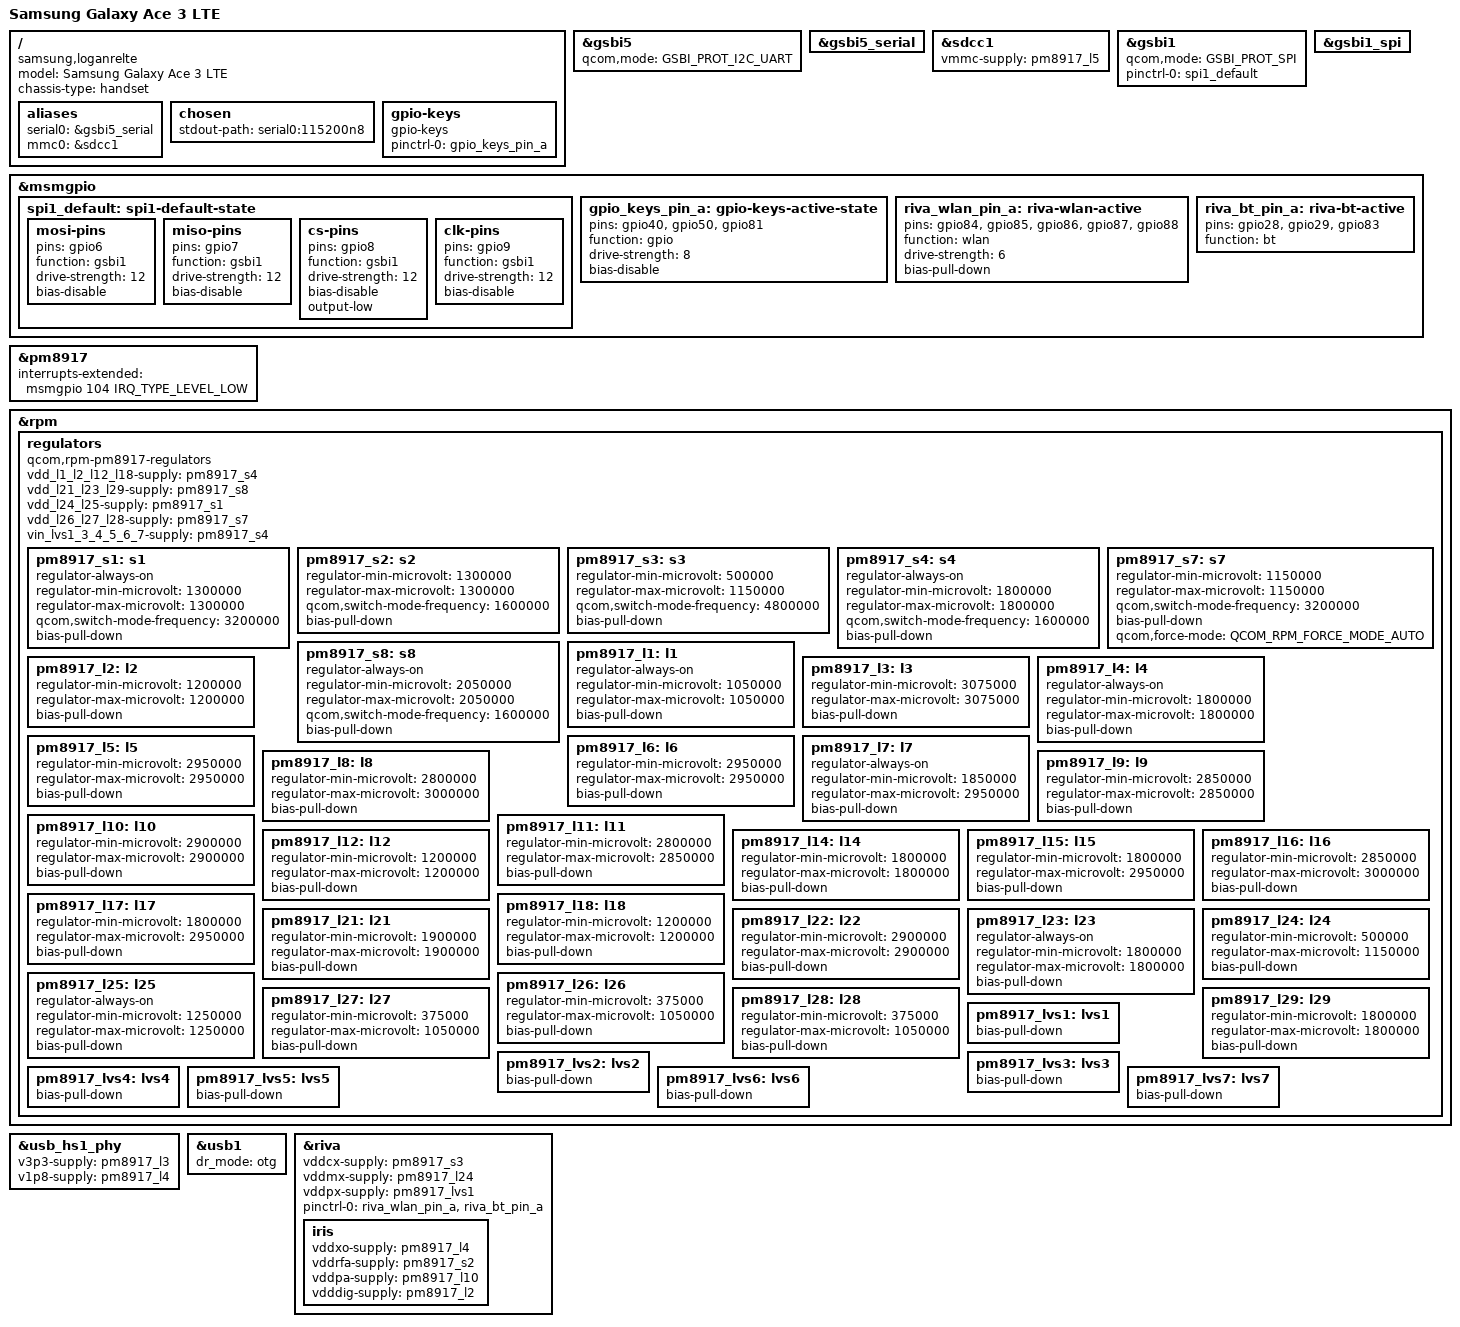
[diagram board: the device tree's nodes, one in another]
// SPDX-License-Identifier: GPL-2.0
// Heavily based on qcom-msm8960-samsung-expressatt.dts

/*
 * TODO:
 * - Enable the uSD card slot
 * - Enable the touchscreen
 * - Enable the screen
 */
#include <dt-bindings/input/input.h>
#include <dt-bindings/reset/qcom,gcc-msm8960.h>

#include "qcom-msm8930-pm8917.dtsi"
#include <dt-bindings/gpio/gpio.h>
#include <dt-bindings/pinctrl/qcom,pmic-gpio.h>
#include <dt-bindings/input/gpio-keys.h>

/ {
	model = "Samsung Galaxy Ace 3 LTE";
	compatible = "samsung,loganrelte", "qcom,msm8930";
	chassis-type = "handset";

	aliases {
		serial0 = &gsbi5_serial;
		mmc0 = &sdcc1; /* SDCC1 eMMC slot */
	};

	chosen {
		stdout-path = "serial0:115200n8";
	};

	gpio-keys {
		compatible = "gpio-keys";
		pinctrl-names = "default";
		pinctrl-0 = <&gpio_keys_pin_a>;
	};
};

&gsbi5 {
	qcom,mode = <GSBI_PROT_I2C_UART>;
	status = "okay";
};

&gsbi5_serial {
	status = "okay";
};

&sdcc1 {
	vmmc-supply = <&pm8917_l5>;
	status = "okay";
};

&gsbi1 {
	qcom,mode = <GSBI_PROT_SPI>;
	pinctrl-0 = <&spi1_default>;
	pinctrl-names = "default";
	status = "okay";
};

&gsbi1_spi {
	status = "okay";
};

&msmgpio {
	spi1_default: spi1-default-state {
		mosi-pins {
			pins = "gpio6";
			function = "gsbi1";
			drive-strength = <12>;
			bias-disable;
		};

		miso-pins {
			pins = "gpio7";
			function = "gsbi1";
			drive-strength = <12>;
			bias-disable;
		};

		cs-pins {
			pins = "gpio8";
			function = "gsbi1";
			drive-strength = <12>;
			bias-disable;
			output-low;
		};

		clk-pins {
			pins = "gpio9";
			function = "gsbi1";
			drive-strength = <12>;
			bias-disable;
		};
	};

	gpio_keys_pin_a: gpio-keys-active-state {
		pins = "gpio40", "gpio50", "gpio81";
		function = "gpio";
		drive-strength = <8>;
		bias-disable;
	};

	riva_wlan_pin_a: riva-wlan-active {
		pins = "gpio84", "gpio85", "gpio86", "gpio87", "gpio88";
		function = "wlan";

		drive-strength = <6>;
		bias-pull-down;
	};

	riva_bt_pin_a: riva-bt-active {
		pins = "gpio28", "gpio29", "gpio83"; // 1 extra ?
		function = "bt";
	};
};

&pm8917 {
	interrupts-extended = <&msmgpio 104 IRQ_TYPE_LEVEL_LOW>;
};

&rpm {
	regulators {
		compatible = "qcom,rpm-pm8917-regulators";
		vdd_l1_l2_l12_l18-supply = <&pm8917_s4>;
		vdd_l21_l23_l29-supply = <&pm8917_s8>;
		vdd_l24_l25-supply = <&pm8917_s1>;
		vdd_l26_l27_l28-supply = <&pm8917_s7>;
		vin_lvs1_3_4_5_6_7-supply = <&pm8917_s4>;

		/* Buck SMPS */
		pm8917_s1: s1 {
			regulator-always-on;
			regulator-min-microvolt = <1300000>;
			regulator-max-microvolt = <1300000>;
			qcom,switch-mode-frequency = <3200000>;
			bias-pull-down;
		};

		pm8917_s2: s2 {
			regulator-min-microvolt = <1300000>;
			regulator-max-microvolt = <1300000>;
			qcom,switch-mode-frequency = <1600000>;
			bias-pull-down;
		};

		pm8917_s3: s3 {
			regulator-min-microvolt = <500000>;
			regulator-max-microvolt = <1150000>;
			qcom,switch-mode-frequency = <4800000>;
			bias-pull-down;
		};

		pm8917_s4: s4 {
			regulator-always-on;
			regulator-min-microvolt = <1800000>;
			regulator-max-microvolt = <1800000>;
			qcom,switch-mode-frequency = <1600000>;
			bias-pull-down;
		};

		pm8917_s7: s7 {
			regulator-min-microvolt = <1150000>;
			regulator-max-microvolt = <1150000>;
			qcom,switch-mode-frequency = <3200000>;
			bias-pull-down;
			qcom,force-mode = <QCOM_RPM_FORCE_MODE_AUTO>;
		};

		pm8917_s8: s8 {
			regulator-always-on;
			regulator-min-microvolt = <2050000>;
			regulator-max-microvolt = <2050000>;
			qcom,switch-mode-frequency = <1600000>;
			bias-pull-down;
		};

		/* PMOS LDO */
		pm8917_l1: l1 {
			regulator-always-on;
			regulator-min-microvolt = <1050000>;
			regulator-max-microvolt = <1050000>;
			bias-pull-down;
		};

		pm8917_l2: l2 {
			regulator-min-microvolt = <1200000>;
			regulator-max-microvolt = <1200000>;
			bias-pull-down;
		};

		pm8917_l3: l3 {
			regulator-min-microvolt = <3075000>;
			regulator-max-microvolt = <3075000>;
			bias-pull-down;
		};

		pm8917_l4: l4 {
			regulator-always-on;
			regulator-min-microvolt = <1800000>;
			regulator-max-microvolt = <1800000>;
			bias-pull-down;
		};

		pm8917_l5: l5 {
			regulator-min-microvolt = <2950000>;
			regulator-max-microvolt = <2950000>;
			bias-pull-down;
		};

		pm8917_l6: l6 {
			regulator-min-microvolt = <2950000>;
			regulator-max-microvolt = <2950000>;
			bias-pull-down;
		};

		pm8917_l7: l7 {
			regulator-always-on;
			regulator-min-microvolt = <1850000>;
			regulator-max-microvolt = <2950000>;
			bias-pull-down;
		};

		pm8917_l8: l8 {
			regulator-min-microvolt = <2800000>;
			regulator-max-microvolt = <3000000>;
			bias-pull-down;
		};

		pm8917_l9: l9 {
			regulator-min-microvolt = <2850000>;
			regulator-max-microvolt = <2850000>;
			bias-pull-down;
		};

		pm8917_l10: l10 {
			regulator-min-microvolt = <2900000>;
			regulator-max-microvolt = <2900000>;
			bias-pull-down;
		};

		pm8917_l11: l11 {
			regulator-min-microvolt = <2800000>;
			regulator-max-microvolt = <2850000>;
			bias-pull-down;
		};

		pm8917_l12: l12 {
			regulator-min-microvolt = <1200000>;
			regulator-max-microvolt = <1200000>;
			bias-pull-down;
		};

		pm8917_l14: l14 {
			regulator-min-microvolt = <1800000>;
			regulator-max-microvolt = <1800000>;
			bias-pull-down;
		};

		pm8917_l15: l15 {
			regulator-min-microvolt = <1800000>;
			regulator-max-microvolt = <2950000>;
			bias-pull-down;
		};

		pm8917_l16: l16 {
			regulator-min-microvolt = <2850000>;
			regulator-max-microvolt = <3000000>;
			bias-pull-down;
		};

		pm8917_l17: l17 {
			regulator-min-microvolt = <1800000>;
			regulator-max-microvolt = <2950000>;
			bias-pull-down;
		};

		pm8917_l18: l18 {
			regulator-min-microvolt = <1200000>;
			regulator-max-microvolt = <1200000>;
			bias-pull-down;
		};

		pm8917_l21: l21 {
			regulator-min-microvolt = <1900000>;
			regulator-max-microvolt = <1900000>;
			bias-pull-down;
		};

		pm8917_l22: l22 {
			regulator-min-microvolt = <2900000>;
			regulator-max-microvolt = <2900000>;
			bias-pull-down;
		};

		pm8917_l23: l23 {
			regulator-always-on;
			regulator-min-microvolt = <1800000>;
			regulator-max-microvolt = <1800000>;
			bias-pull-down;
		};

		pm8917_l24: l24 {
			regulator-min-microvolt = <500000>;
			regulator-max-microvolt = <1150000>;
			bias-pull-down;
		};

		pm8917_l25: l25 {
			regulator-always-on;
			regulator-min-microvolt = <1250000>;
			regulator-max-microvolt = <1250000>;
			bias-pull-down;
		};

		pm8917_l26: l26 {
			regulator-min-microvolt = <375000>;
			regulator-max-microvolt = <1050000>;
			bias-pull-down;
		};

		pm8917_l27: l27 {
			regulator-min-microvolt = <375000>;
			regulator-max-microvolt = <1050000>;
			bias-pull-down;
		};

		pm8917_l28: l28 {
			regulator-min-microvolt = <375000>;
			regulator-max-microvolt = <1050000>;
			bias-pull-down;
		};

		pm8917_l29: l29 {
			regulator-min-microvolt = <1800000>;
			regulator-max-microvolt = <1800000>;
			bias-pull-down;
		};

		// TODO: l30 - l36

		/* Low Voltage Switch */
		pm8917_lvs1: lvs1 {
			bias-pull-down;
		};

		pm8917_lvs2: lvs2 {
			bias-pull-down;
		};

		pm8917_lvs3: lvs3 {
			bias-pull-down;
		};

		pm8917_lvs4: lvs4 {
			bias-pull-down;
		};

		pm8917_lvs5: lvs5 {
			bias-pull-down;
		};

		pm8917_lvs6: lvs6 {
			bias-pull-down;
		};

		pm8917_lvs7: lvs7 {
			bias-pull-down;
		};

		// TODO: boost and usb
	};
};

&usb_hs1_phy {
	v3p3-supply = <&pm8917_l3>;
	v1p8-supply = <&pm8917_l4>;
};

&usb1 {
	dr_mode = "otg";
	status = "okay";
};

&riva {
	vddcx-supply = <&pm8917_s3>;
	vddmx-supply = <&pm8917_l24>;
	vddpx-supply = <&pm8917_lvs1>;

	pinctrl-0 = <&riva_wlan_pin_a>, <&riva_bt_pin_a>;
	pinctrl-names = "default";

	status = "okay";

	iris {
		vddxo-supply = <&pm8917_l4>;
		vddrfa-supply = <&pm8917_s2>;
		vddpa-supply = <&pm8917_l10>;
		vdddig-supply = <&pm8917_l2>;
		// vddio lvs4
	};

};
